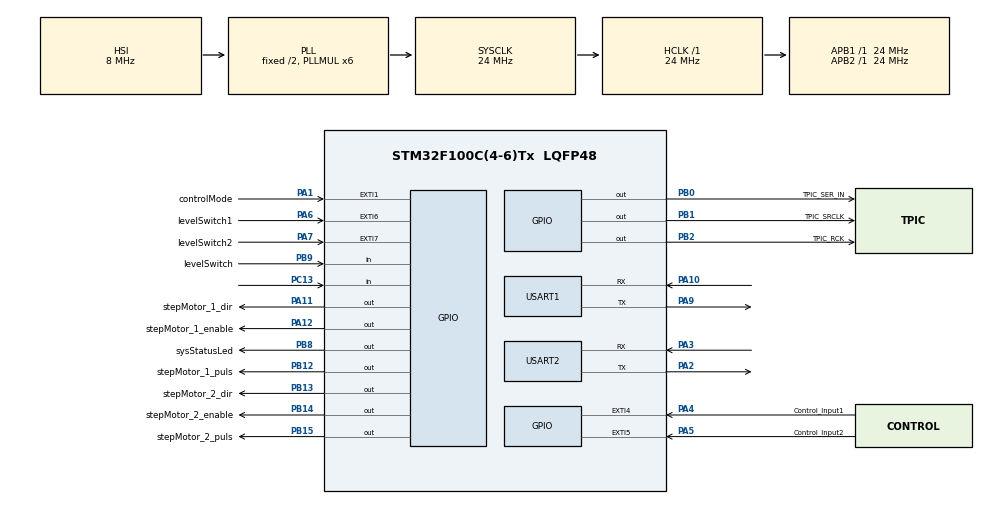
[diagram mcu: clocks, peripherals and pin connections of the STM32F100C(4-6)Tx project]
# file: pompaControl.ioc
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Mcu.Family=STM32F1
Mcu.Name=STM32F100C(4-6)Tx
Mcu.Package=LQFP48
NVIC.EXTI1_IRQn=true\:0\:0\:false\:false\:true\:true\:true\:true
NVIC.EXTI4_IRQn=true\:0\:0\:false\:false\:true\:true\:true\:true
NVIC.EXTI9_5_IRQn=true\:0\:0\:false\:false\:true\:true\:true\:true
NVIC.PriorityGroup=NVIC_PRIORITYGROUP_4
NVIC.RTC_Alarm_IRQn=true\:0\:0\:false\:false\:true\:true\:true\:true
NVIC.RTC_IRQn=true\:0\:0\:false\:false\:true\:true\:true\:true
NVIC.TIM2_IRQn=true\:0\:0\:false\:false\:true\:true\:true\:true
NVIC.USART1_IRQn=true\:0\:0\:false\:false\:true\:true\:true\:true
NVIC.USART2_IRQn=true\:0\:0\:false\:false\:true\:true\:true\:true
PA1.GPIO_Label=controlMode
PA1.Signal=GPXTI1
PA10.Mode=Asynchronous
PA10.Signal=USART1_RX
PA11.GPIO_Label=stepMotor_1_dir
PA11.GPIO_PuPd=GPIO_PULLDOWN
PA11.Signal=GPIO_Output
PA12.GPIO_Label=stepMotor_1_enable
PA12.GPIO_PuPd=GPIO_PULLUP
PA12.Signal=GPIO_Output
PA13.Mode=Serial_Wire
PA13.Signal=SYS_JTMS-SWDIO
PA14.Mode=Serial_Wire
PA14.Signal=SYS_JTCK-SWCLK
PA2.Mode=Asynchronous
PA2.Signal=USART2_TX
PA3.Mode=Asynchronous
PA3.Signal=USART2_RX
PA4.GPIO_Label=Control_Input1
PA4.Signal=GPXTI4
PA5.GPIO_Label=Control_Input2
PA5.Signal=GPXTI5
PA6.GPIO_Label=levelSwitch1
PA6.Signal=GPXTI6
PA7.GPIO_Label=levelSwitch2
PA7.Signal=GPXTI7
PA9.Mode=Asynchronous
PA9.Signal=USART1_TX
PB0.GPIO_Label=TPIC_SER_IN
PB0.Signal=GPIO_Output
PB1.GPIO_Label=TPIC_SRCLK
PB1.GPIO_Speed=GPIO_SPEED_FREQ_HIGH
PB1.Signal=GPIO_Output
PB12.GPIO_Label=stepMotor_1_puls
PB12.GPIO_Speed=GPIO_SPEED_FREQ_HIGH
PB12.Signal=GPIO_Output
PB13.GPIO_Label=stepMotor_2_dir
PB13.GPIO_PuPd=GPIO_PULLDOWN
PB13.Signal=GPIO_Output
PB14.GPIO_Label=stepMotor_2_enable
PB14.GPIO_PuPd=GPIO_PULLUP
PB14.Signal=GPIO_Output
PB15.GPIO_Label=stepMotor_2_puls
PB15.GPIO_Speed=GPIO_SPEED_FREQ_HIGH
PB15.Signal=GPIO_Output
PB2.GPIO_Label=TPIC_RCK
PB2.Signal=GPIO_Output
PB8.GPIO_Label=sysStatusLed
PB8.Signal=GPIO_Output
PB9.GPIO_Label=levelSwitch
PB9.Signal=GPIO_Input
PC13-TAMPER-RTC.Signal=GPIO_Input
PC14-OSC32_IN.Mode=LSE-External-Oscillator
PC14-OSC32_IN.Signal=RCC_OSC32_IN
PC15-OSC32_OUT.Mode=LSE-External-Oscillator
PC15-OSC32_OUT.Signal=RCC_OSC32_OUT
PD0-OSC_IN.Mode=HSE-External-Oscillator
PD0-OSC_IN.Signal=RCC_OSC_IN
PD1-OSC_OUT.Mode=HSE-External-Oscillator
PD1-OSC_OUT.Signal=RCC_OSC_OUT
ProjectManager.HeapSize=0x200
ProjectManager.StackSize=0x400
ProjectManager.TargetToolchain=STM32CubeIDE
RCC.AHBFreq_Value=24000000
RCC.APB1Freq_Value=24000000
RCC.APB1TimFreq_Value=24000000
RCC.APB2Freq_Value=24000000
RCC.APB2TimFreq_Value=24000000
RCC.HCLKFreq_Value=24000000
RCC.PLLMUL=RCC_PLL_MUL6
RCC.RTCClockSelection=RCC_RTCCLKSOURCE_LSE
RCC.SYSCLKFreq_VALUE=24000000
RCC.SYSCLKSource=RCC_SYSCLKSOURCE_PLLCLK
TIM2.Period=500
TIM2.Prescaler=48
USART1.VirtualMode=VM_ASYNC
USART2.VirtualMode=VM_ASYNC
VP_IWDG_VS_IWDG.Mode=IWDG_Activate
VP_RTC_VS_RTC_Activate.Mode=RTC_Enabled
VP_RTC_VS_RTC_Calendar.Mode=RTC_Calendar
VP_TIM1_VS_ClockSourceITR.Mode=TriggerSource_ITR0
VP_TIM2_VS_ClockSourceITR.Mode=TriggerSource_ITR1
board=custom

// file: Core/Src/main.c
/* USER CODE BEGIN Header */
/**
  ******************************************************************************
  * @file           : main.c
  * @brief          : Main program body
  ******************************************************************************
  * @attention
  *
  * Copyright (c) 2023 STMicroelectronics.
  * All rights reserved.
  *
  * This software is licensed under terms that can be found in the LICENSE file
  * in the root directory of this software component.
  * If no LICENSE file comes with this software, it is provided AS-IS.
  *
  ******************************************************************************
  */
/* USER CODE END Header */
#include "main.h"

IWDG_HandleTypeDef hiwdg;

RTC_HandleTypeDef hrtc;

TIM_HandleTypeDef htim1;
TIM_HandleTypeDef htim2;

UART_HandleTypeDef huart1;
UART_HandleTypeDef huart2;

void SystemClock_Config(void);
static void MX_GPIO_Init(void);
static void MX_RTC_Init(void);
static void MX_USART1_UART_Init(void);
static void MX_USART2_UART_Init(void);
static void MX_TIM1_Init(void);
static void MX_TIM2_Init(void);
static void MX_IWDG_Init(void);

int main(void)
{

  /* MCU Configuration--------------------------------------------------------*/

  /* Reset of all peripherals, Initializes the Flash interface and the Systick. */
  HAL_Init();

  /* Configure the system clock */
  SystemClock_Config();

  /* Initialize all configured peripherals */
  MX_GPIO_Init();
  MX_RTC_Init();
  MX_USART1_UART_Init();
  MX_USART2_UART_Init();
  MX_TIM1_Init();
  MX_TIM2_Init();
  MX_IWDG_Init();
  /* USER CODE BEGIN 2 */

  __HAL_IWDG_START(&hiwdg);

  /* TPIC Register */

  /* step motor init */

  /* modbus */

  /* USER CODE END 2 */

  /* Infinite loop */
  /* USER CODE BEGIN WHILE */
  while (1)
  {
	  process_requests();
    /* USER CODE END WHILE */

  }
}

void SystemClock_Config(void)
{
  RCC_OscInitTypeDef RCC_OscInitStruct = {0};
  RCC_ClkInitTypeDef RCC_ClkInitStruct = {0};
  RCC_PeriphCLKInitTypeDef PeriphClkInit = {0};

  /** Initializes the RCC Oscillators according to the specified parameters
  * in the RCC_OscInitTypeDef structure.
  */
  RCC_OscInitStruct.OscillatorType = RCC_OSCILLATORTYPE_HSI|RCC_OSCILLATORTYPE_LSI
                              |RCC_OSCILLATORTYPE_LSE;
  RCC_OscInitStruct.LSEState = RCC_LSE_ON;
  RCC_OscInitStruct.HSIState = RCC_HSI_ON;
  RCC_OscInitStruct.HSICalibrationValue = RCC_HSICALIBRATION_DEFAULT;
  RCC_OscInitStruct.LSIState = RCC_LSI_ON;
  RCC_OscInitStruct.PLL.PLLState = RCC_PLL_ON;
  RCC_OscInitStruct.PLL.PLLSource = RCC_PLLSOURCE_HSI_DIV2;
  RCC_OscInitStruct.PLL.PLLMUL = RCC_PLL_MUL6;
  if (HAL_RCC_OscConfig(&RCC_OscInitStruct) != HAL_OK)
  {
    Error_Handler();
  }

  /** Initializes the CPU, AHB and APB buses clocks
  */
  RCC_ClkInitStruct.ClockType = RCC_CLOCKTYPE_HCLK|RCC_CLOCKTYPE_SYSCLK
                              |RCC_CLOCKTYPE_PCLK1|RCC_CLOCKTYPE_PCLK2;
  RCC_ClkInitStruct.SYSCLKSource = RCC_SYSCLKSOURCE_PLLCLK;
  RCC_ClkInitStruct.AHBCLKDivider = RCC_SYSCLK_DIV1;
  RCC_ClkInitStruct.APB1CLKDivider = RCC_HCLK_DIV1;
  RCC_ClkInitStruct.APB2CLKDivider = RCC_HCLK_DIV1;

  if (HAL_RCC_ClockConfig(&RCC_ClkInitStruct, FLASH_LATENCY_0) != HAL_OK)
  {
    Error_Handler();
  }
  PeriphClkInit.PeriphClockSelection = RCC_PERIPHCLK_RTC;
  PeriphClkInit.RTCClockSelection = RCC_RTCCLKSOURCE_LSE;
  if (HAL_RCCEx_PeriphCLKConfig(&PeriphClkInit) != HAL_OK)
  {
    Error_Handler();
  }
}

static void MX_IWDG_Init(void)
{

  hiwdg.Instance = IWDG;
  hiwdg.Init.Prescaler = IWDG_PRESCALER_4;
  hiwdg.Init.Reload = 4095;
  if (HAL_IWDG_Init(&hiwdg) != HAL_OK)
  {
    Error_Handler();
  }

}

static void MX_RTC_Init(void)
{

  RTC_TimeTypeDef sTime = {0};
  RTC_DateTypeDef DateToUpdate = {0};

  /** Initialize RTC Only
  */
  hrtc.Instance = RTC;
  hrtc.Init.AsynchPrediv = RTC_AUTO_1_SECOND;
  hrtc.Init.OutPut = RTC_OUTPUTSOURCE_ALARM;
  if (HAL_RTC_Init(&hrtc) != HAL_OK)
  {
    Error_Handler();
  }

  /** Initialize RTC and set the Time and Date
  */
  sTime.Hours = 0x0;
  sTime.Minutes = 0x0;
  sTime.Seconds = 0x0;

  if (HAL_RTC_SetTime(&hrtc, &sTime, RTC_FORMAT_BCD) != HAL_OK)
  {
    Error_Handler();
  }
  DateToUpdate.WeekDay = RTC_WEEKDAY_MONDAY;
  DateToUpdate.Month = RTC_MONTH_JANUARY;
  DateToUpdate.Date = 0x1;
  DateToUpdate.Year = 0x0;

  if (HAL_RTC_SetDate(&hrtc, &DateToUpdate, RTC_FORMAT_BCD) != HAL_OK)
  {
    Error_Handler();
  }

}

static void MX_TIM1_Init(void)
{

  TIM_SlaveConfigTypeDef sSlaveConfig = {0};
  TIM_MasterConfigTypeDef sMasterConfig = {0};

  htim1.Instance = TIM1;
  htim1.Init.Prescaler = 0;
  htim1.Init.CounterMode = TIM_COUNTERMODE_UP;
  htim1.Init.Period = 65535;
  htim1.Init.ClockDivision = TIM_CLOCKDIVISION_DIV1;
  htim1.Init.RepetitionCounter = 0;
  htim1.Init.AutoReloadPreload = TIM_AUTORELOAD_PRELOAD_DISABLE;
  if (HAL_TIM_Base_Init(&htim1) != HAL_OK)
  {
    Error_Handler();
  }
  sSlaveConfig.SlaveMode = TIM_SLAVEMODE_DISABLE;
  sSlaveConfig.InputTrigger = TIM_TS_ITR0;
  if (HAL_TIM_SlaveConfigSynchro(&htim1, &sSlaveConfig) != HAL_OK)
  {
    Error_Handler();
  }
  sMasterConfig.MasterOutputTrigger = TIM_TRGO_RESET;
  sMasterConfig.MasterSlaveMode = TIM_MASTERSLAVEMODE_DISABLE;
  if (HAL_TIMEx_MasterConfigSynchronization(&htim1, &sMasterConfig) != HAL_OK)
  {
    Error_Handler();
  }

}

static void MX_TIM2_Init(void)
{

  TIM_SlaveConfigTypeDef sSlaveConfig = {0};
  TIM_MasterConfigTypeDef sMasterConfig = {0};

  htim2.Instance = TIM2;
  htim2.Init.Prescaler = 48;
  htim2.Init.CounterMode = TIM_COUNTERMODE_UP;
  htim2.Init.Period = 500;
  htim2.Init.ClockDivision = TIM_CLOCKDIVISION_DIV1;
  htim2.Init.AutoReloadPreload = TIM_AUTORELOAD_PRELOAD_DISABLE;
  if (HAL_TIM_Base_Init(&htim2) != HAL_OK)
  {
    Error_Handler();
  }
  sSlaveConfig.SlaveMode = TIM_SLAVEMODE_DISABLE;
  sSlaveConfig.InputTrigger = TIM_TS_ITR1;
  if (HAL_TIM_SlaveConfigSynchro(&htim2, &sSlaveConfig) != HAL_OK)
  {
    Error_Handler();
  }
  sMasterConfig.MasterOutputTrigger = TIM_TRGO_RESET;
  sMasterConfig.MasterSlaveMode = TIM_MASTERSLAVEMODE_DISABLE;
  if (HAL_TIMEx_MasterConfigSynchronization(&htim2, &sMasterConfig) != HAL_OK)
  {
    Error_Handler();
  }

}

static void MX_USART1_UART_Init(void)
{

  huart1.Instance = USART1;
  huart1.Init.BaudRate = 115200;
  huart1.Init.WordLength = UART_WORDLENGTH_8B;
  huart1.Init.StopBits = UART_STOPBITS_1;
  huart1.Init.Parity = UART_PARITY_NONE;
  huart1.Init.Mode = UART_MODE_TX_RX;
  huart1.Init.HwFlowCtl = UART_HWCONTROL_NONE;
  huart1.Init.OverSampling = UART_OVERSAMPLING_16;
  if (HAL_UART_Init(&huart1) != HAL_OK)
  {
    Error_Handler();
  }

}

static void MX_USART2_UART_Init(void)
{

  huart2.Instance = USART2;
  huart2.Init.BaudRate = 115200;
  huart2.Init.WordLength = UART_WORDLENGTH_8B;
  huart2.Init.StopBits = UART_STOPBITS_1;
  huart2.Init.Parity = UART_PARITY_NONE;
  huart2.Init.Mode = UART_MODE_TX_RX;
  huart2.Init.HwFlowCtl = UART_HWCONTROL_NONE;
  huart2.Init.OverSampling = UART_OVERSAMPLING_16;
  if (HAL_UART_Init(&huart2) != HAL_OK)
  {
    Error_Handler();
  }

}

static void MX_GPIO_Init(void)
{
  GPIO_InitTypeDef GPIO_InitStruct = {0};

  /* GPIO Ports Clock Enable */
  __HAL_RCC_GPIOC_CLK_ENABLE();
  __HAL_RCC_GPIOD_CLK_ENABLE();
  __HAL_RCC_GPIOA_CLK_ENABLE();
  __HAL_RCC_GPIOB_CLK_ENABLE();

  /*Configure GPIO pin Output Level */
  HAL_GPIO_WritePin(GPIOB, TPIC_SER_IN_Pin|TPIC_SRCLK_Pin|TPIC_RCK_Pin|stepMotor_1_puls_Pin
                          |stepMotor_2_dir_Pin|stepMotor_2_enable_Pin|stepMotor_2_puls_Pin|sysStatusLed_Pin, GPIO_PIN_RESET);

  /*Configure GPIO pin Output Level */
  HAL_GPIO_WritePin(GPIOA, stepMotor_1_dir_Pin|stepMotor_1_enable_Pin, GPIO_PIN_RESET);

  /*Configure GPIO pin : PC13 */
  GPIO_InitStruct.Pin = GPIO_PIN_13;
  GPIO_InitStruct.Mode = GPIO_MODE_INPUT;
  GPIO_InitStruct.Pull = GPIO_NOPULL;
  HAL_GPIO_Init(GPIOC, &GPIO_InitStruct);

  /*Configure GPIO pins : controlMode_Pin Control_Input1_Pin Control_Input2_Pin levelSwitch1_Pin
                           levelSwitch2_Pin */
  GPIO_InitStruct.Pin = controlMode_Pin|Control_Input1_Pin|Control_Input2_Pin|levelSwitch1_Pin
                          |levelSwitch2_Pin;
  GPIO_InitStruct.Mode = GPIO_MODE_IT_RISING;
  GPIO_InitStruct.Pull = GPIO_NOPULL;
  HAL_GPIO_Init(GPIOA, &GPIO_InitStruct);

  /*Configure GPIO pins : TPIC_SER_IN_Pin TPIC_RCK_Pin sysStatusLed_Pin */
  GPIO_InitStruct.Pin = TPIC_SER_IN_Pin|TPIC_RCK_Pin|sysStatusLed_Pin;
  GPIO_InitStruct.Mode = GPIO_MODE_OUTPUT_PP;
  GPIO_InitStruct.Pull = GPIO_NOPULL;
  GPIO_InitStruct.Speed = GPIO_SPEED_FREQ_LOW;
  HAL_GPIO_Init(GPIOB, &GPIO_InitStruct);

  /*Configure GPIO pins : TPIC_SRCLK_Pin stepMotor_1_puls_Pin stepMotor_2_puls_Pin */
  GPIO_InitStruct.Pin = TPIC_SRCLK_Pin|stepMotor_1_puls_Pin|stepMotor_2_puls_Pin;
  GPIO_InitStruct.Mode = GPIO_MODE_OUTPUT_PP;
  GPIO_InitStruct.Pull = GPIO_NOPULL;
  GPIO_InitStruct.Speed = GPIO_SPEED_FREQ_HIGH;
  HAL_GPIO_Init(GPIOB, &GPIO_InitStruct);

  /*Configure GPIO pin : stepMotor_2_dir_Pin */
  GPIO_InitStruct.Pin = stepMotor_2_dir_Pin;
  GPIO_InitStruct.Mode = GPIO_MODE_OUTPUT_PP;
  GPIO_InitStruct.Pull = GPIO_PULLDOWN;
  GPIO_InitStruct.Speed = GPIO_SPEED_FREQ_LOW;
  HAL_GPIO_Init(stepMotor_2_dir_GPIO_Port, &GPIO_InitStruct);

  /*Configure GPIO pin : stepMotor_2_enable_Pin */
  GPIO_InitStruct.Pin = stepMotor_2_enable_Pin;
  GPIO_InitStruct.Mode = GPIO_MODE_OUTPUT_PP;
  GPIO_InitStruct.Pull = GPIO_PULLUP;
  GPIO_InitStruct.Speed = GPIO_SPEED_FREQ_LOW;
  HAL_GPIO_Init(stepMotor_2_enable_GPIO_Port, &GPIO_InitStruct);

  /*Configure GPIO pin : stepMotor_1_dir_Pin */
  GPIO_InitStruct.Pin = stepMotor_1_dir_Pin;
  GPIO_InitStruct.Mode = GPIO_MODE_OUTPUT_PP;
  GPIO_InitStruct.Pull = GPIO_PULLDOWN;
  GPIO_InitStruct.Speed = GPIO_SPEED_FREQ_LOW;
  HAL_GPIO_Init(stepMotor_1_dir_GPIO_Port, &GPIO_InitStruct);

  /*Configure GPIO pin : stepMotor_1_enable_Pin */
  GPIO_InitStruct.Pin = stepMotor_1_enable_Pin;
  GPIO_InitStruct.Mode = GPIO_MODE_OUTPUT_PP;
  GPIO_InitStruct.Pull = GPIO_PULLUP;
  GPIO_InitStruct.Speed = GPIO_SPEED_FREQ_LOW;
  HAL_GPIO_Init(stepMotor_1_enable_GPIO_Port, &GPIO_InitStruct);

  /*Configure GPIO pin : levelSwitch_Pin */
  GPIO_InitStruct.Pin = levelSwitch_Pin;
  GPIO_InitStruct.Mode = GPIO_MODE_INPUT;
  GPIO_InitStruct.Pull = GPIO_NOPULL;
  HAL_GPIO_Init(levelSwitch_GPIO_Port, &GPIO_InitStruct);

  /* EXTI interrupt init*/
  HAL_NVIC_SetPriority(EXTI1_IRQn, 0, 0);
  HAL_NVIC_EnableIRQ(EXTI1_IRQn);

  HAL_NVIC_SetPriority(EXTI4_IRQn, 0, 0);
  HAL_NVIC_EnableIRQ(EXTI4_IRQn);

  HAL_NVIC_SetPriority(EXTI9_5_IRQn, 0, 0);
  HAL_NVIC_EnableIRQ(EXTI9_5_IRQn);

}

void Error_Handler(void)
{
  __disable_irq();
  while (1)
  {
  }
}
